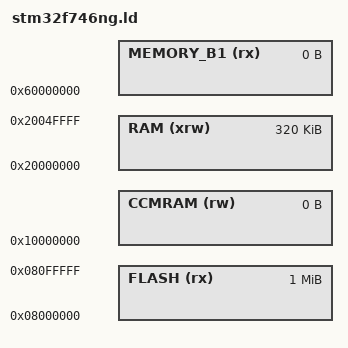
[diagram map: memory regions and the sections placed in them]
/* Specify the memory areas */
MEMORY
{
  FLASH (rx)      : ORIGIN = 0x08000000, LENGTH = 1M
  RAM (xrw)       : ORIGIN = 0x20000000, LENGTH = 320K
  MEMORY_B1 (rx)  : ORIGIN = 0x60000000, LENGTH = 0K
  CCMRAM (rw)     : ORIGIN = 0x10000000, LENGTH = 0K
}
